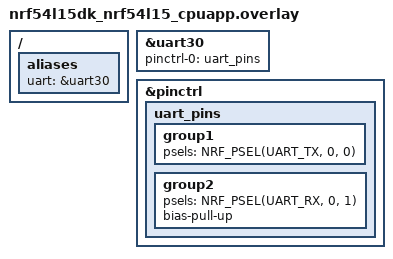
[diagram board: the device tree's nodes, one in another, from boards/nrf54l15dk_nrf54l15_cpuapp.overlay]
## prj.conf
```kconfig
# Disable optimizations
CONFIG_NO_OPTIMIZATIONS=y
# Include GPIO driver in system config ( Kconfig )
CONFIG_SERIAL=y
```

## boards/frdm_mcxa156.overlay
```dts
/ {
    aliases {
        uart = &lpuart0;
    };  
};

/*enable and configure pins for the uart 0*/
&lpuart0 {
    status = "okay";
    pinctrl-0 = <&uart_pins>;
	pinctrl-names = "default";
};

/*configure uart pins as Tx and Rx pins*/
&pinctrl {
	uart_pins: uart_pins {
		group0 {
			pinmux = <LPUART0_RXD_P0_2>, <LPUART0_TXD_P0_3>;
            slew-rate = "fast";
			drive-strength = "low";
			input-enable;
        };
    };
};
```

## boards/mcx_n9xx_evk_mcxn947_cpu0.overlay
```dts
/ {
    aliases {
        uart = &flexcomm4_lpuart4;
    };  
};

/*enable and configure pins for the uart 4*/
&flexcomm4_lpuart4 {
    status = "okay";
    pinctrl-0 = <&uart_pins>;
	pinctrl-names = "default";
};

/*configure uart pins as Tx and Rx pins*/
&pinctrl {
	uart_pins: uart_pins {
		group0 {
			pinmux = <FC4_P0_PIO1_8>, <FC4_P1_PIO1_9>;
            slew-rate = "fast";
			drive-strength = "low";
			input-enable;
			bias-pull-up;
        };
    };
};
```

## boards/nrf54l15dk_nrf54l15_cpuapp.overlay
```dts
/ {
    aliases {
        uart = &uart30;
    };  
};

/*enable and configure pins for the uart 30*/
&uart30 {
    status = "okay";
    pinctrl-0 = <&uart_pins>;
	pinctrl-names = "default", "sleep";
};

/*configure uart pins as Tx and Rx pins*/
&pinctrl {
	uart_pins: uart_pins {
		group1 {
			psels = <NRF_PSEL(UART_TX, 0, 0)>;
		};

        group2 {
			psels = <NRF_PSEL(UART_RX, 0, 1)>;
			bias-pull-up;
		};
    };
};
```

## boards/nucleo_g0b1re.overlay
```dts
/ {
    aliases {
        uart = &usart2;
    };  
};

/*configure the usart 2. ST already ships pins configuration
definition as part of the hal_smt32 module, refer to 
stm32g0b1c(b-c-e)tx-pinctrl.dtsi and stm32g0b1c(b-c-e)ixn-pinctrl.dtsi*/
&usart2 {
    status = "okay";
	pinctrl-0 = <&usart2_tx_pa2 &usart2_rx_pa3>;
	pinctrl-names = "default";
};
```

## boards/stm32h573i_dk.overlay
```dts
/ {
    aliases {
        uart = &usart1;
    };  
};

/*configure the usart 1. ST already ships pins configuration
definition as part of the hal_smt32 module, refer to stm32h573iikxq-pinctrl.dtsi*/
&usart2 {
    status = "okay";
	pinctrl-0 = <&usart1_tx_pa9 &usart1_rx_pa10>;
	pinctrl-names = "default";
};
```

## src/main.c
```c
/**
 * @file main.c
 * @brief Change UART runtime configuration sample
 * 
 * This sample application shows how to change the UART runtime configuration 
 * using the UART HAL driver API. the uart_config structure is filled with the 
 * desired configuration and then applied using the uart_configure() function.
 * 
 * NOTE: By default one uart is always configured to be used for the printk()
 * function. Just take a look at your board's .dts file to see which uart is
 * used for that purpose and avoid using it in this sample.
 */
#include <zephyr/kernel.h>
#include <zephyr/drivers/uart.h>

/* Get the device tree name for the uart port using an alias, 
as it is defined in the device tree file*/
const struct device *uart_dev = DEVICE_DT_GET( DT_ALIAS( uart ) );

int main( void )
{
    /* Configuration structure */
    struct uart_config uart_cfg;
    
    uart_cfg.baudrate  = 115200;
    uart_cfg.data_bits = UART_CFG_DATA_BITS_8;
    uart_cfg.stop_bits = UART_CFG_STOP_BITS_1;
    uart_cfg.flow_ctrl = UART_CFG_FLOW_CTRL_NONE;
    uart_cfg.parity    = UART_CFG_PARITY_NONE;    
    /* Set UART configuration */
    uart_configure( uart_dev, &uart_cfg );

    while(1)
    {
        /* send just one single character and wait until is sended */
        uart_poll_out( uart_dev, 'Y' );
        k_msleep( 1000 );
    }
    return 0;
}
```
